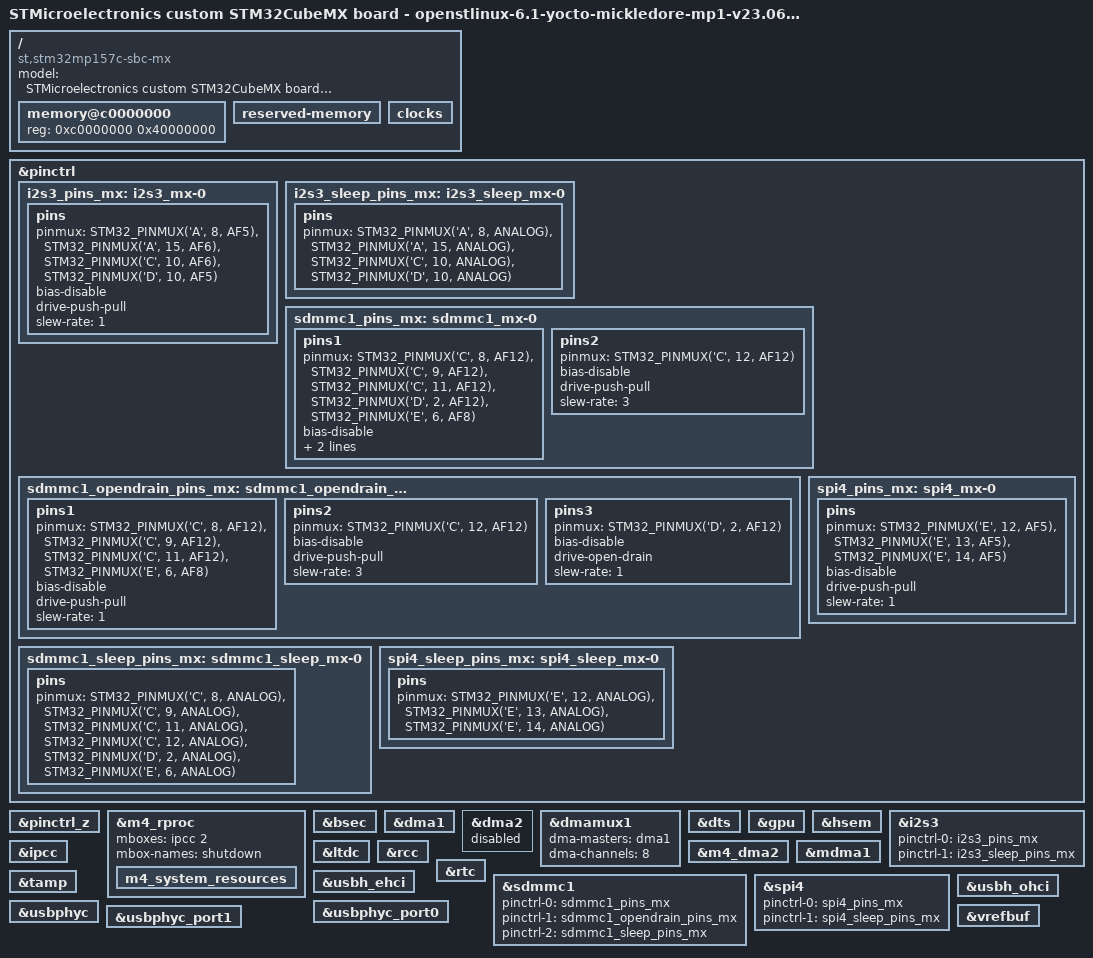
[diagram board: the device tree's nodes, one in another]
// SPDX-License-Identifier: (GPL-2.0-or-later OR BSD-3-Clause)
/*
 * Copyright (C) 2023, STMicroelectronics - All Rights Reserved
 * Author: STM32CubeMX code generation for STMicroelectronics.
 */

/* For more information on Device Tree configuration, please refer to
 * https://wiki.st.com/stm32mpu/wiki/Category:Device_tree_configuration
 */

/dts-v1/;
#include <dt-bindings/pinctrl/stm32-pinfunc.h>

#include "stm32mp157.dtsi"
#include "stm32mp15xc.dtsi"
#include "stm32mp15xxad-pinctrl.dtsi"
#include "stm32mp15-m4-srm.dtsi"

/* USER CODE BEGIN includes */
/* USER CODE END includes */

/ {
	model = "STMicroelectronics custom STM32CubeMX board - openstlinux-6.1-yocto-mickledore-mp1-v23.06.21";
	compatible = "st,stm32mp157c-sbc-mx", "st,stm32mp157";

	memory@c0000000 {
		device_type = "memory";
		reg = <0xc0000000 0x40000000>;

		/* USER CODE BEGIN memory */
		/* USER CODE END memory */
	};

	reserved-memory {
		#address-cells = <1>;
		#size-cells = <1>;
		ranges;

		/* USER CODE BEGIN reserved-memory */
		/* USER CODE END reserved-memory */
	};

	/* USER CODE BEGIN root */
	/* USER CODE END root */

	clocks{

		/* USER CODE BEGIN clocks */
		/* USER CODE END clocks */
	};

}; /*root*/

&pinctrl {

	i2s3_pins_mx: i2s3_mx-0 {
		pins {
			pinmux = <STM32_PINMUX('A', 8, AF5)>, /* I2S3_SDO */
					 <STM32_PINMUX('A', 15, AF6)>, /* I2S3_WS */
					 <STM32_PINMUX('C', 10, AF6)>, /* I2S3_CK */
					 <STM32_PINMUX('D', 10, AF5)>; /* I2S3_SDI */
			bias-disable;
			drive-push-pull;
			slew-rate = <1>;
		};
	};

	i2s3_sleep_pins_mx: i2s3_sleep_mx-0 {
		pins {
			pinmux = <STM32_PINMUX('A', 8, ANALOG)>, /* I2S3_SDO */
					 <STM32_PINMUX('A', 15, ANALOG)>, /* I2S3_WS */
					 <STM32_PINMUX('C', 10, ANALOG)>, /* I2S3_CK */
					 <STM32_PINMUX('D', 10, ANALOG)>; /* I2S3_SDI */
		};
	};

	sdmmc1_pins_mx: sdmmc1_mx-0 {
		pins1 {
			pinmux = <STM32_PINMUX('C', 8, AF12)>, /* SDMMC1_D0 */
					 <STM32_PINMUX('C', 9, AF12)>, /* SDMMC1_D1 */
					 <STM32_PINMUX('C', 11, AF12)>, /* SDMMC1_D3 */
					 <STM32_PINMUX('D', 2, AF12)>, /* SDMMC1_CMD */
					 <STM32_PINMUX('E', 6, AF8)>; /* SDMMC1_D2 */
			bias-disable;
			drive-push-pull;
			slew-rate = <1>;
		};
		pins2 {
			pinmux = <STM32_PINMUX('C', 12, AF12)>; /* SDMMC1_CK */
			bias-disable;
			drive-push-pull;
			slew-rate = <3>;
		};
	};

	sdmmc1_opendrain_pins_mx: sdmmc1_opendrain_mx-0 {
		pins1 {
			pinmux = <STM32_PINMUX('C', 8, AF12)>, /* SDMMC1_D0 */
					 <STM32_PINMUX('C', 9, AF12)>, /* SDMMC1_D1 */
					 <STM32_PINMUX('C', 11, AF12)>, /* SDMMC1_D3 */
					 <STM32_PINMUX('E', 6, AF8)>; /* SDMMC1_D2 */
			bias-disable;
			drive-push-pull;
			slew-rate = <1>;
		};
		pins2 {
			pinmux = <STM32_PINMUX('C', 12, AF12)>; /* SDMMC1_CK */
			bias-disable;
			drive-push-pull;
			slew-rate = <3>;
		};
		pins3 {
			pinmux = <STM32_PINMUX('D', 2, AF12)>; /* SDMMC1_CMD */
			bias-disable;
			drive-open-drain;
			slew-rate = <1>;
		};
	};

	sdmmc1_sleep_pins_mx: sdmmc1_sleep_mx-0 {
		pins {
			pinmux = <STM32_PINMUX('C', 8, ANALOG)>, /* SDMMC1_D0 */
					 <STM32_PINMUX('C', 9, ANALOG)>, /* SDMMC1_D1 */
					 <STM32_PINMUX('C', 11, ANALOG)>, /* SDMMC1_D3 */
					 <STM32_PINMUX('C', 12, ANALOG)>, /* SDMMC1_CK */
					 <STM32_PINMUX('D', 2, ANALOG)>, /* SDMMC1_CMD */
					 <STM32_PINMUX('E', 6, ANALOG)>; /* SDMMC1_D2 */
		};
	};

	spi4_pins_mx: spi4_mx-0 {
		pins {
			pinmux = <STM32_PINMUX('E', 12, AF5)>, /* SPI4_SCK */
					 <STM32_PINMUX('E', 13, AF5)>, /* SPI4_MISO */
					 <STM32_PINMUX('E', 14, AF5)>; /* SPI4_MOSI */
			bias-disable;
			drive-push-pull;
			slew-rate = <1>;
		};
	};

	spi4_sleep_pins_mx: spi4_sleep_mx-0 {
		pins {
			pinmux = <STM32_PINMUX('E', 12, ANALOG)>, /* SPI4_SCK */
					 <STM32_PINMUX('E', 13, ANALOG)>, /* SPI4_MISO */
					 <STM32_PINMUX('E', 14, ANALOG)>; /* SPI4_MOSI */
		};
	};

	/* USER CODE BEGIN pinctrl */
	/* USER CODE END pinctrl */
};

&pinctrl_z {

	/* USER CODE BEGIN pinctrl_z */
	/* USER CODE END pinctrl_z */
};

&m4_rproc{
	/*Restriction: "memory-region" property is not managed - please to use User-Section if needed*/
	mboxes = <&ipcc 2>;
	mbox-names = "shutdown";
	status = "okay";

	/* USER CODE BEGIN m4_rproc */
	/* USER CODE END m4_rproc */

	m4_system_resources{
		status = "okay";

		/* USER CODE BEGIN m4_system_resources */
		/* USER CODE END m4_system_resources */
	};
};

&bsec{
	status = "okay";

	/* USER CODE BEGIN bsec */
	/* USER CODE END bsec */
};

&dma1{
	status = "okay";

	/* USER CODE BEGIN dma1 */
	/* USER CODE END dma1 */
};

&dma2{
	status = "disabled";

	/* USER CODE BEGIN dma2 */
	/* USER CODE END dma2 */
};

&dmamux1{
	status = "okay";

	dma-masters = <&dma1>;
	dma-channels = <8>;

	/* USER CODE BEGIN dmamux1 */
	/* USER CODE END dmamux1 */
};

&dts{
	status = "okay";

	/* USER CODE BEGIN dts */
	/* USER CODE END dts */
};

&gpu{
	status = "okay";

	/* USER CODE BEGIN gpu */
	/* USER CODE END gpu */
};

&hsem{
	status = "okay";

	/* USER CODE BEGIN hsem */
	/* USER CODE END hsem */
};

&i2s3{
	pinctrl-names = "default", "sleep";
	pinctrl-0 = <&i2s3_pins_mx>;
	pinctrl-1 = <&i2s3_sleep_pins_mx>;
	status = "okay";

	/* USER CODE BEGIN i2s3 */
	/* USER CODE END i2s3 */
};

&ipcc{
	status = "okay";

	/* USER CODE BEGIN ipcc */
	/* USER CODE END ipcc */
};

&ltdc{
	status = "okay";

	/* USER CODE BEGIN ltdc */
	/* USER CODE END ltdc */
};

&m4_dma2{
	status = "okay";

	/* USER CODE BEGIN m4_dma2 */
	/* USER CODE END m4_dma2 */
};

&mdma1{
	status = "okay";

	/* USER CODE BEGIN mdma1 */
	/* USER CODE END mdma1 */
};

&rcc{
	status = "okay";

	/* USER CODE BEGIN rcc */
	/* USER CODE END rcc */
};

&rtc{
	status = "okay";

	/* USER CODE BEGIN rtc */
	/* USER CODE END rtc */
};

&sdmmc1{
	pinctrl-names = "default", "opendrain", "sleep";
	pinctrl-0 = <&sdmmc1_pins_mx>;
	pinctrl-1 = <&sdmmc1_opendrain_pins_mx>;
	pinctrl-2 = <&sdmmc1_sleep_pins_mx>;
	status = "okay";

	/* USER CODE BEGIN sdmmc1 */
	/* USER CODE END sdmmc1 */
};

&spi4{
	pinctrl-names = "default", "sleep";
	pinctrl-0 = <&spi4_pins_mx>;
	pinctrl-1 = <&spi4_sleep_pins_mx>;
	status = "okay";

	/* USER CODE BEGIN spi4 */
	/* USER CODE END spi4 */
};

&tamp{
	status = "okay";

	/* USER CODE BEGIN tamp */
	/* USER CODE END tamp */
};

&usbh_ehci{
	status = "okay";

	/* USER CODE BEGIN usbh_ehci */
	/* USER CODE END usbh_ehci */
};

&usbh_ohci{
	status = "okay";

	/* USER CODE BEGIN usbh_ohci */
	/* USER CODE END usbh_ohci */
};

&usbphyc{
	status = "okay";

	/* USER CODE BEGIN usbphyc */
	/* USER CODE END usbphyc */
};

&usbphyc_port0{
	status = "okay";

	/* USER CODE BEGIN usbphyc_port0 */
	/* USER CODE END usbphyc_port0 */
};

&usbphyc_port1{
	status = "okay";

	/* USER CODE BEGIN usbphyc_port1 */
	/* USER CODE END usbphyc_port1 */
};

&vrefbuf{
	status = "okay";

	/* USER CODE BEGIN vrefbuf */
	/* USER CODE END vrefbuf */
};

/* USER CODE BEGIN addons */
/* USER CODE END addons */

